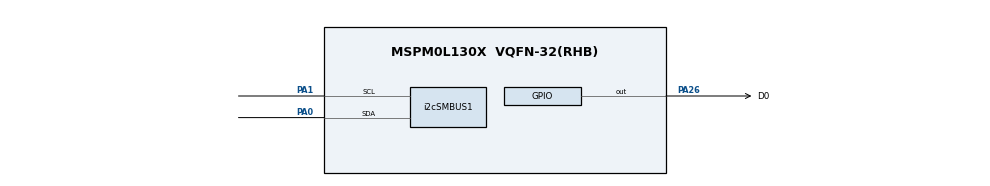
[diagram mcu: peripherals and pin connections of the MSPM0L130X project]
// @cliArgs --device "MSPM0L130X" --package "VQFN-32(RHB)" --part "Default"
// @cliArgs --board /ti/boards/LP_MSPM0L1306 --rtos nortos

/**
 * Import the modules used in this configuration.
 */
const ProjectConfig = scripting.addModule("/ti/project_config/ProjectConfig");
const Board     = scripting.addModule("/ti/driverlib/Board");
const GPIO      = scripting.addModule("/ti/driverlib/GPIO", {}, false);
const GPIO1     = GPIO.addInstance();
const i2cSMBUS  = scripting.addModule("/ti/driverlib/i2cSMBUS", {}, false);
const i2cSMBUS1 = i2cSMBUS.addInstance();

/**
 * Write custom configuration values to the imported modules.
 */
ProjectConfig.genLibPMBUS     = true;

GPIO1.$name                         = "GPIO_LED";
GPIO1.associatedPins[0].$name       = "D0";
GPIO1.associatedPins[0].pin.$assign = "PA26";

const SYSCTL = scripting.addModule("/ti/driverlib/SYSCTL", {}, false);

i2cSMBUS1.basicEnableController             = true;
i2cSMBUS1.$name                             = "SMB_I2C";
i2cSMBUS1.enableTimeoutA                    = true;
i2cSMBUS1.intGeneric                        = ["TIMEOUT_A"];
i2cSMBUS1.enableControllerPEC               = true;
i2cSMBUS1.intController                     = ["ARBITRATION_LOST","NACK","PEC_RX_ERROR","RXFIFO_TRIGGER","START","STOP","TXFIFO_TRIGGER"];
i2cSMBUS1.timeoutACount                     = 135;
i2cSMBUS1.peripheral.$assign                = "I2C0";
i2cSMBUS1.peripheral.sdaPin.$assign         = "PA0";
i2cSMBUS1.peripheral.sclPin.$assign         = "PA1";
